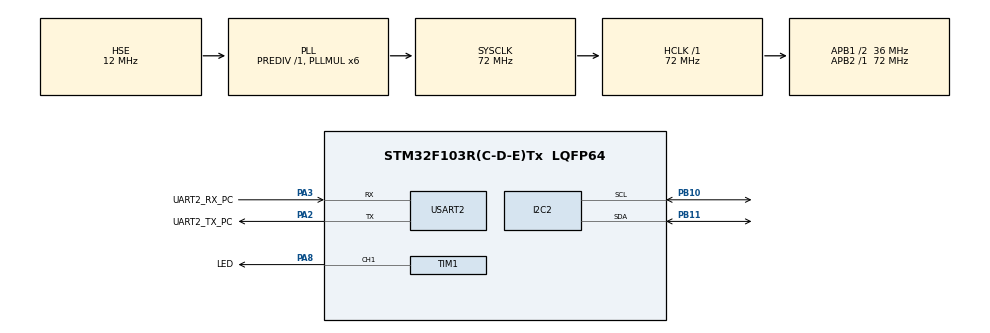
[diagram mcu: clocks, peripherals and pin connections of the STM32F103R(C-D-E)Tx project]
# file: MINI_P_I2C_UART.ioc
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Dma.Request0=USART2_RX
Dma.Request1=USART2_TX
Dma.USART2_RX.0.Direction=DMA_PERIPH_TO_MEMORY
Dma.USART2_RX.0.Instance=DMA1_Channel6
Dma.USART2_RX.0.MemDataAlignment=DMA_MDATAALIGN_BYTE
Dma.USART2_RX.0.MemInc=DMA_MINC_ENABLE
Dma.USART2_RX.0.Mode=DMA_CIRCULAR
Dma.USART2_RX.0.PeriphDataAlignment=DMA_PDATAALIGN_BYTE
Dma.USART2_RX.0.PeriphInc=DMA_PINC_DISABLE
Dma.USART2_RX.0.Priority=DMA_PRIORITY_LOW
Dma.USART2_TX.1.Direction=DMA_MEMORY_TO_PERIPH
Dma.USART2_TX.1.Instance=DMA1_Channel7
Dma.USART2_TX.1.MemDataAlignment=DMA_MDATAALIGN_BYTE
Dma.USART2_TX.1.MemInc=DMA_MINC_ENABLE
Dma.USART2_TX.1.Mode=DMA_NORMAL
Dma.USART2_TX.1.PeriphDataAlignment=DMA_PDATAALIGN_BYTE
Dma.USART2_TX.1.PeriphInc=DMA_PINC_DISABLE
Dma.USART2_TX.1.Priority=DMA_PRIORITY_LOW
FREERTOS.INCLUDE_vTaskDelayUntil=1
FREERTOS.Tasks01=UserTask,0,256,StartUserTask,As weak,NULL,Dynamic,NULL,NULL
FREERTOS.configTOTAL_HEAP_SIZE=4096
FREERTOS.configUSE_COUNTING_SEMAPHORES=1
FREERTOS.configUSE_TICKLESS_IDLE=0
FREERTOS.configUSE_TICK_HOOK=0
FREERTOS.configUSE_TIMERS=0
I2C2.I2C_Mode=I2C_Fast
Mcu.Family=STM32F1
Mcu.Name=STM32F103R(C-D-E)Tx
Mcu.Package=LQFP64
NVIC.DMA1_Channel6_IRQn=true\:5\:0\:false\:false\:true\:true\:false
NVIC.DMA1_Channel7_IRQn=true\:5\:0\:false\:false\:true\:true\:false
NVIC.I2C2_ER_IRQn=true\:5\:0\:false\:false\:true\:true\:true
NVIC.I2C2_EV_IRQn=true\:5\:0\:false\:false\:true\:true\:true
NVIC.PriorityGroup=NVIC_PRIORITYGROUP_4
NVIC.TIM8_UP_IRQn=true\:0\:0\:false\:false\:true\:false\:false
NVIC.TimeBase=TIM8_UP_IRQn
NVIC.TimeBaseIP=TIM8
NVIC.USART2_IRQn=true\:5\:0\:false\:false\:true\:true\:true
PA13.Mode=Serial_Wire
PA13.Signal=SYS_JTMS-SWDIO
PA14.Mode=Serial_Wire
PA14.Signal=SYS_JTCK-SWCLK
PA2.GPIO_Label=UART2_TX_PC
PA2.Mode=Asynchronous
PA2.Signal=USART2_TX
PA3.GPIO_Label=UART2_RX_PC
PA3.Mode=Asynchronous
PA3.Signal=USART2_RX
PA8.GPIO_Label=LED
PA8.Signal=S_TIM1_CH1
PB10.Mode=I2C
PB10.Signal=I2C2_SCL
PB11.Mode=I2C
PB11.Signal=I2C2_SDA
PD0-OSC_IN.Mode=HSE-External-Oscillator
PD0-OSC_IN.Signal=RCC_OSC_IN
PD1-OSC_OUT.Mode=HSE-External-Oscillator
PD1-OSC_OUT.Signal=RCC_OSC_OUT
ProjectManager.HeapSize=0x800
ProjectManager.StackSize=0x400
ProjectManager.TargetToolchain=MDK-ARM V5
RCC.AHBFreq_Value=72000000
RCC.APB1CLKDivider=RCC_HCLK_DIV2
RCC.APB1Freq_Value=36000000
RCC.APB1TimFreq_Value=72000000
RCC.APB2Freq_Value=72000000
RCC.APB2TimFreq_Value=72000000
RCC.HCLKFreq_Value=72000000
RCC.HSE_VALUE=12000000
RCC.PLLMUL=RCC_PLL_MUL6
RCC.PLLSourceVirtual=RCC_PLLSOURCE_HSE
RCC.SYSCLKFreq_VALUE=72000000
RCC.SYSCLKSource=RCC_SYSCLKSOURCE_PLLCLK
RCC.USBFreq_Value=72000000
SH.S_TIM1_CH1.0=TIM1_CH1,PWM Generation1 CH1
TIM1.Channel-PWM\ Generation1\ CH1=TIM_CHANNEL_1
TIM1.Period=10000
TIM1.Prescaler=0
USART2.VirtualMode=VM_ASYNC
VP_FREERTOS_VS_ENABLE.Mode=Enabled
VP_SYS_VS_tim8.Mode=TIM8
board=custom

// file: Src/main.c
/* USER CODE BEGIN Header */
/**
  ******************************************************************************
  * @file           : main.c
  * @brief          : Main program body
  ******************************************************************************
  * This notice applies to any and all portions of this file
  * that are not between comment pairs USER CODE BEGIN and
  * USER CODE END. Other portions of this file, whether
  * inserted by the user or by software development tools
  * are owned by their respective copyright owners.
  *
  * Copyright (c) 2019 STMicroelectronics International N.V.
  * All rights reserved.
  *
  * Redistribution and use in source and binary forms, with or without
  * modification, are permitted, provided that the following conditions are met:
  *
  * 1. Redistribution of source code must retain the above copyright notice,
  *    this list of conditions and the following disclaimer.
  * 2. Redistributions in binary form must reproduce the above copyright notice,
  *    this list of conditions and the following disclaimer in the documentation
  *    and/or other materials provided with the distribution.
  * 3. Neither the name of STMicroelectronics nor the names of other
  *    contributors to this software may be used to endorse or promote products
  *    derived from this software without specific written permission.
  * 4. This software, including modifications and/or derivative works of this
  *    software, must execute solely and exclusively on microcontroller or
  *    microprocessor devices manufactured by or for STMicroelectronics.
  * 5. Redistribution and use of this software other than as permitted under
  *    this license is void and will automatically terminate your rights under
  *    this license.
  *
  * THIS SOFTWARE IS PROVIDED BY STMICROELECTRONICS AND CONTRIBUTORS "AS IS"
  * AND ANY EXPRESS, IMPLIED OR STATUTORY WARRANTIES, INCLUDING, BUT NOT
  * LIMITED TO, THE IMPLIED WARRANTIES OF MERCHANTABILITY, FITNESS FOR A
  * PARTICULAR PURPOSE AND NON-INFRINGEMENT OF THIRD PARTY INTELLECTUAL PROPERTY
  * RIGHTS ARE DISCLAIMED TO THE FULLEST EXTENT PERMITTED BY LAW. IN NO EVENT
  * SHALL STMICROELECTRONICS OR CONTRIBUTORS BE LIABLE FOR ANY DIRECT, INDIRECT,
  * INCIDENTAL, SPECIAL, EXEMPLARY, OR CONSEQUENTIAL DAMAGES (INCLUDING, BUT NOT
  * LIMITED TO, PROCUREMENT OF SUBSTITUTE GOODS OR SERVICES; LOSS OF USE, DATA,
  * OR PROFITS; OR BUSINESS INTERRUPTION) HOWEVER CAUSED AND ON ANY THEORY OF
  * LIABILITY, WHETHER IN CONTRACT, STRICT LIABILITY, OR TORT (INCLUDING
  * NEGLIGENCE OR OTHERWISE) ARISING IN ANY WAY OUT OF THE USE OF THIS SOFTWARE,
  * EVEN IF ADVISED OF THE POSSIBILITY OF SUCH DAMAGE.
  *
  ******************************************************************************
  */
/* USER CODE END Header */

#include "main.h"
#include "cmsis_os.h"
#include "dma.h"
#include "i2c.h"
#include "tim.h"
#include "usart.h"
#include "gpio.h"

/* USER CODE BEGIN Includes */
#include "SEGGER_SYSVIEW.h"
#include "bsp_uart.h"
/* USER CODE END Includes */

/* USER CODE BEGIN PV */
/* Private variables ---------------------------------------------------------*/

/* USER CODE END PV */

void SystemClock_Config(void);
void MX_FREERTOS_Init(void);
/* USER CODE BEGIN PFP */
/* Private function prototypes -----------------------------------------------*/

/* USER CODE END PFP */

int main(void)
{

  /* MCU Configuration--------------------------------------------------------*/

  /* Reset of all peripherals, Initializes the Flash interface and the Systick. */
  HAL_Init();

  /* Configure the system clock */
  SystemClock_Config();

  /* Initialize all configured peripherals */
  MX_GPIO_Init();
  MX_DMA_Init();
  MX_USART2_UART_Init();
  MX_TIM1_Init();
  MX_I2C2_Init();
  /* USER CODE BEGIN 2 */
  BspUartInit();
  SEGGER_SYSVIEW_Conf(); /* Configure and initialize SystemView */
  /* USER CODE END 2 */

  /* Call init function for freertos objects (in freertos.c) */
  MX_FREERTOS_Init();

  /* Start scheduler */
  osKernelStart();

  /* We should never get here as control is now taken by the scheduler */

  /* Infinite loop */
  while (1)
  {

  }
}

void SystemClock_Config(void)
{
  RCC_OscInitTypeDef RCC_OscInitStruct = {0};
  RCC_ClkInitTypeDef RCC_ClkInitStruct = {0};

  /**Initializes the CPU, AHB and APB busses clocks
  */
  RCC_OscInitStruct.OscillatorType = RCC_OSCILLATORTYPE_HSE;
  RCC_OscInitStruct.HSEState = RCC_HSE_ON;
  RCC_OscInitStruct.HSEPredivValue = RCC_HSE_PREDIV_DIV1;
  RCC_OscInitStruct.HSIState = RCC_HSI_ON;
  RCC_OscInitStruct.PLL.PLLState = RCC_PLL_ON;
  RCC_OscInitStruct.PLL.PLLSource = RCC_PLLSOURCE_HSE;
  RCC_OscInitStruct.PLL.PLLMUL = RCC_PLL_MUL6;
  if (HAL_RCC_OscConfig(&RCC_OscInitStruct) != HAL_OK)
  {
    Error_Handler();
  }
  /**Initializes the CPU, AHB and APB busses clocks
  */
  RCC_ClkInitStruct.ClockType = RCC_CLOCKTYPE_HCLK|RCC_CLOCKTYPE_SYSCLK
                              |RCC_CLOCKTYPE_PCLK1|RCC_CLOCKTYPE_PCLK2;
  RCC_ClkInitStruct.SYSCLKSource = RCC_SYSCLKSOURCE_PLLCLK;
  RCC_ClkInitStruct.AHBCLKDivider = RCC_SYSCLK_DIV1;
  RCC_ClkInitStruct.APB1CLKDivider = RCC_HCLK_DIV2;
  RCC_ClkInitStruct.APB2CLKDivider = RCC_HCLK_DIV1;

  if (HAL_RCC_ClockConfig(&RCC_ClkInitStruct, FLASH_LATENCY_2) != HAL_OK)
  {
    Error_Handler();
  }
}

void HAL_TIM_PeriodElapsedCallback(TIM_HandleTypeDef *htim)
{
  if (htim->Instance == TIM8) {
    HAL_IncTick();
  }
}

void Error_Handler(void)
{
  while(1)
  {
  }
}

/************************ (C) COPYRIGHT STMicroelectronics *****END OF FILE****/

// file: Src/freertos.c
/* USER CODE BEGIN Header */
/**
  ******************************************************************************
  * File Name          : freertos.c
  * Description        : Code for freertos applications
  ******************************************************************************
  * This notice applies to any and all portions of this file
  * that are not between comment pairs USER CODE BEGIN and
  * USER CODE END. Other portions of this file, whether
  * inserted by the user or by software development tools
  * are owned by their respective copyright owners.
  *
  * Copyright (c) 2018 STMicroelectronics International N.V.
  * All rights reserved.
  *
  * Redistribution and use in source and binary forms, with or without
  * modification, are permitted, provided that the following conditions are met:
  *
  * 1. Redistribution of source code must retain the above copyright notice,
  *    this list of conditions and the following disclaimer.
  * 2. Redistributions in binary form must reproduce the above copyright notice,
  *    this list of conditions and the following disclaimer in the documentation
  *    and/or other materials provided with the distribution.
  * 3. Neither the name of STMicroelectronics nor the names of other
  *    contributors to this software may be used to endorse or promote products
  *    derived from this software without specific written permission.
  * 4. This software, including modifications and/or derivative works of this
  *    software, must execute solely and exclusively on microcontroller or
  *    microprocessor devices manufactured by or for STMicroelectronics.
  * 5. Redistribution and use of this software other than as permitted under
  *    this license is void and will automatically terminate your rights under
  *    this license.
  *
  * THIS SOFTWARE IS PROVIDED BY STMICROELECTRONICS AND CONTRIBUTORS "AS IS"
  * AND ANY EXPRESS, IMPLIED OR STATUTORY WARRANTIES, INCLUDING, BUT NOT
  * LIMITED TO, THE IMPLIED WARRANTIES OF MERCHANTABILITY, FITNESS FOR A
  * PARTICULAR PURPOSE AND NON-INFRINGEMENT OF THIRD PARTY INTELLECTUAL PROPERTY
  * RIGHTS ARE DISCLAIMED TO THE FULLEST EXTENT PERMITTED BY LAW. IN NO EVENT
  * SHALL STMICROELECTRONICS OR CONTRIBUTORS BE LIABLE FOR ANY DIRECT, INDIRECT,
  * INCIDENTAL, SPECIAL, EXEMPLARY, OR CONSEQUENTIAL DAMAGES (INCLUDING, BUT NOT
  * LIMITED TO, PROCUREMENT OF SUBSTITUTE GOODS OR SERVICES; LOSS OF USE, DATA,
  * OR PROFITS; OR BUSINESS INTERRUPTION) HOWEVER CAUSED AND ON ANY THEORY OF
  * LIABILITY, WHETHER IN CONTRACT, STRICT LIABILITY, OR TORT (INCLUDING
  * NEGLIGENCE OR OTHERWISE) ARISING IN ANY WAY OUT OF THE USE OF THIS SOFTWARE,
  * EVEN IF ADVISED OF THE POSSIBILITY OF SUCH DAMAGE.
  *
  ******************************************************************************
  */
/* USER CODE END Header */

#include "FreeRTOS.h"
#include "task.h"
#include "main.h"
#include "cmsis_os.h"

osThreadId UserTaskHandle;

void StartUserTask(void const * argument);

void MX_FREERTOS_Init(void); /* (MISRA C 2004 rule 8.1) */

void MX_FREERTOS_Init(void) {

  /* Create the thread(s) */
  /* definition and creation of UserTask */
  osThreadDef(UserTask, StartUserTask, osPriorityNormal, 0, 256);
  UserTaskHandle = osThreadCreate(osThread(UserTask), NULL);

}

__weak void StartUserTask(void const * argument)
{

  for(;;)
  {
    osDelay(1);
  }
}

/************************ (C) COPYRIGHT STMicroelectronics *****END OF FILE****/
